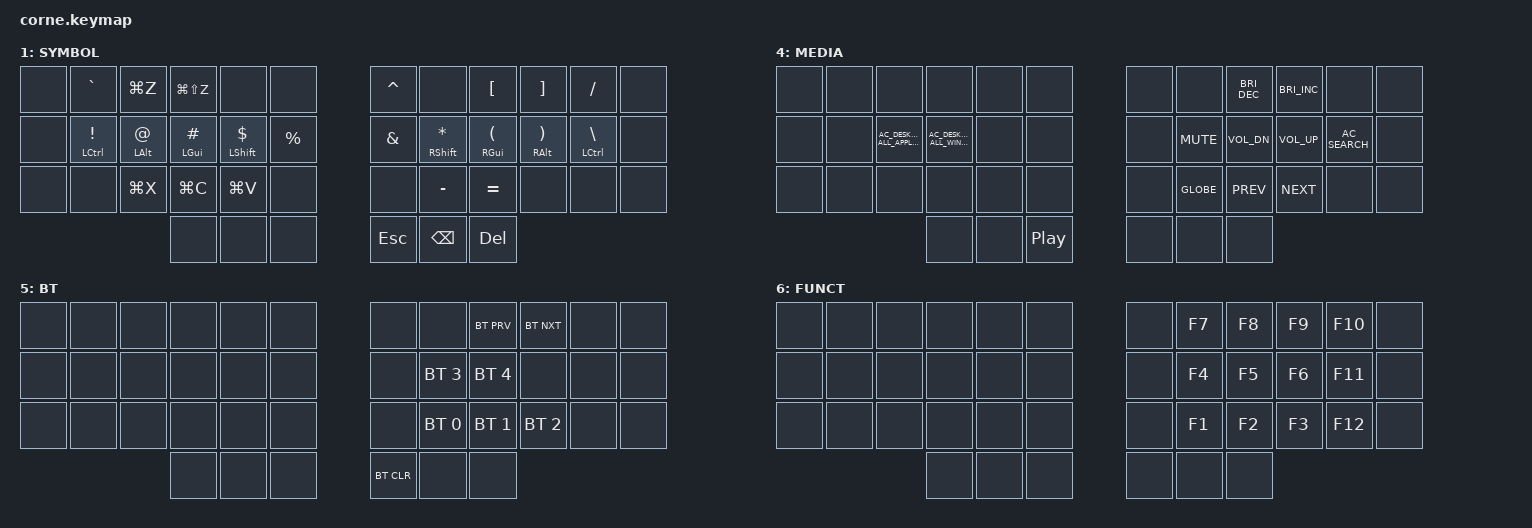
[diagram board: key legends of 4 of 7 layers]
/*
 * Copyright (c) 2020 The ZMK Contributors
 *
 * SPDX-License-Identifier: MIT
 */

#include <behaviors.dtsi>
#include <dt-bindings/zmk/keys.h>
#include <dt-bindings/zmk/bt.h>
#include "./keypos42.h"
#include "./helpers.h"

// Define my layers
#define DEFAULT 0
#define SYM 1
#define NUM 2
#define NAV 3
#define MEDIA 4
#define BT 5
#define FUN 6


// Define custom keys shortform
#define XX &none
#define MEH LG(LA(LCTRL))
#define HYP LS(LG(LA(LCTRL)))
#define REM LA(BSPC)
#define KCUT &kp LG(X)
#define KCOPY &kp LG(C)
#define KPASTE &kp LG(V)
#define KUNDO &kp LG(Z)
#define KREDO &kp LG(LS(Z))
#define MUL &kp KP_MULTIPLY
#define SUB &kp KP_SUBTRACT
#define ADD &kp KP_PLUS
#define DIV &kp KP_DIVIDE
#define KEQ &kp KP_EQUAL
#define KP0 &kp KP_N0
#define K1 &kp KP_N1
#define K2 &kp KP_N2
#define K3 &kp KP_N3
#define K4 &kp KP_N4
#define K5 &kp KP_N5
#define K6 &kp KP_N6
#define C6 KP_N6
#define K7 &kp KP_N7
#define C7 KP_N7
#define K8 &kp KP_N8
#define C8 KP_N8
#define K9 &kp KP_N9
#define VOL_UP &kp C_VOL_UP
#define VOL_DOWN &kp C_VOL_DN
#define BR_UP &kp C_BRIGHTNESS_INC
#define BR_DOWN &kp C_BRIGHTNESS_DEC
#define MUTE &kp K_MUTE
#define PLAY &kp C_PLAY
#define PAUSE &kp C_PAUSE
#define PREV &kp C_PREV
#define NEXT &kp C_NEXT
#define STOP &kp C_STOP
#define SLEEP &kp C_SLEEP
#define POWER &kp C_POWER
#define CALC &kp C_CALCULATOR
#define PP &kp C_PLAY_PAUSE
#define SEARCH &kp C_AC_SEARCH
#define EXPOSE &kp C_AC_DESKTOP_SHOW_ALL_WINDOWS
#define APPS &kp C_AC_DESKTOP_SHOW_ALL_APPLICATIONS
#define PERC &kp PRCNT
#define AMPER &kp AMPS

/* Homerow mods */

#define KEYS_L LT0 LT1 LT2 LT3 LT4 LM0 LM1 LM2 LM3 LM4 LB0 LB1 LB2 LB3 LB4  // left hand
#define KEYS_R RT0 RT1 RT2 RT3 RT4 RM0 RM1 RM2 RM3 RM4 RB0 RB1 RB2 RB3 RB4  // right hand
#define THUMBS LH2 LH1 LH0 RH0 RH1 RH2                                      // thumbs

&lt {
        tapping-term-ms = <200>;
};

&sk {
        release-after-ms = <2000>;
        quick-release;
};

/ {
        combos {
                compatible = "zmk,combos";
                combo_capslock {
                        timeout-ms = <40>;
                        key-positions = <LH1 RH1>;
                        bindings = <&kp CAPS>;
                };
        };
        behaviors {
                hml: left_hand_positional_hold_tap {
                        compatible = "zmk,behavior-hold-tap";
                        label = "LEFT_POSITIONAL_HOLD_TAP";
                        #binding-cells = <2>;
                        flavor = "balanced";
                        tapping-term-ms = <280>;                        // <---[[produces tap if held longer than tapping-term-ms]]
                        require-prior-idle-ms = <180>;
                        quick-tap-ms = <175>;
                        bindings = <&kp>, <&kp>;
                        hold-trigger-key-positions = <KEYS_R THUMBS>;    // <---[[right-hand keys]]
                        hold-trigger-on-release;
                };
                hmr: right_hand_positional_hold_tap {
                        compatible = "zmk,behavior-hold-tap";
                        label = "RIGHT_POSITIONAL_HOLD_TAP";
                        #binding-cells = <2>;
                        flavor = "balanced";
                        tapping-term-ms = <280>;                        // <---[[produces tap if held longer than tapping-term-ms]]
                        require-prior-idle-ms = <180>;
                        quick-tap-ms = <175>;
                        bindings = <&kp>, <&kp>;
                        hold-trigger-key-positions = <KEYS_L THUMBS>;    // <---[[left-hand keys]]
                        hold-trigger-on-release;
                };
        };
        keymap {
                compatible = "zmk,keymap";
                default_layer {
                        label = "BASE";
                        bindings = <
//╭─────────────┬─────────────┬─────────────┬─────────────┬─────────────╮╭─────────────┬─────────────┬─────────────┬─────────────┬─────────────╮
XX  &kp SQT       &kp COMMA     &kp DOT       &kp P           &kp Y         &kp F        &kp G         &kp C         &kp R         &kp L       XX
//├─────────────┼─────────────┼─────────────┼─────────────┼─────────────┤├─────────────┼─────────────┼─────────────┼─────────────┼─────────────┤
XX &hml LCTRL A  &hml LALT O   &hml LGUI E   &hml LSHFT U     &kp I         &kp D       &hmr RSHFT H  &hmr RGUI T   &hmr RALT N   &hmr LCTRL S XX
//├─────────────┼─────────────┼─────────────┼─────────────┼─────────────┤├─────────────┼─────────────┼─────────────┼─────────────┼─────────────┤
XX  &lt FUN SEMI  &kp Q         &kp J         &kp K           &kp X         &kp B        &kp M         &kp W         &kp V         &kp Z       XX
//╰─────────────┴─────────────┼─────────────┼─────────────┼─────────────┤├─────────────┼─────────────┼─────────────┼─────-───────┴─────────────╯
                                &lt BT XX     &lt NUM TAB  &lt SYM REM   &lt NAV SPACE  &sk LSHIFT   &lt MEDIA RET
//                            ╰─────────────┴─────────────┴─────────────╯╰─────────────┴─────────────┴─────────────╯
                        >;
                };
                symbol_layer {
                        label = "SYMBOL";
                        bindings = <
//╭─────────────┬─────────────┬─────────────┬─────────────┬─────────────╮╭─────────────┬─────────────┬─────────────┬─────────────┬─────────────╮
XX  &kp GRAVE       KUNDO          KREDO         XX             XX         &kp CARET         XX        &kp LBKT       &kp RBKT    &kp FSLH     XX
//├─────────────┼─────────────┼─────────────┼─────────────┼─────────────┤├─────────────┼─────────────┼─────────────┼─────────────┼─────────────┤
XX &hml LCTRL EXCL &hml LALT AT &hml LGUI HASH &hml LSHFT DLLR  PERC       AMPER &hmr RSHFT STAR &hmr RGUI LPAR &hmr RALT RPAR &hmr LCTRL BSLH XX
//├─────────────┼─────────────┼─────────────┼─────────────┼─────────────┤├─────────────┼─────────────┼─────────────┼─────────────┼─────────────┤
XX      XX            KCUT         KCOPY          KPASTE         XX          XX            &kp MINUS    &kp EQUAL        XX           XX       XX
//╰─────────────┴─────────────┼─────────────┼─────────────┼─────────────┤├─────────────┼─────────────┼─────────────┼─────-───────┴─────────────╯
                                    XX            XX            XX          &kp ESC        &kp BSPC     &kp DEL     
//                            ╰─────────────┴─────────────┴─────────────╯╰─────────────┴─────────────┴─────────────╯
                        >;
                };
                number_layer {
                        label = "NUMBER";
                        bindings = <
//╭─────────────┬─────────────┬─────────────┬─────────────┬─────────────╮╭─────────────┬─────────────┬─────────────┬─────────────┬─────────────╮
XX  &kp SQT       &kp LBKT       &kp RBKT        XX             XX            KEQ         &kp N7        &kp N8        &kp N9       &kp MINUS   XX
//├─────────────┼─────────────┼─────────────┼─────────────┼─────────────┤├─────────────┼─────────────┼─────────────┼─────────────┼─────────────┤
XX &hml LCTRL XX &hml LALT LPAR &hml LGUI RPAR &hml LSHFT SPACE XX            MUL      &hmr RSHFT N4 &hmr RGUI N5 &hmr RALT N6 &hmr LCTRL PLUS XX
//├─────────────┼─────────────┼─────────────┼─────────────┼─────────────┤├─────────────┼─────────────┼─────────────┼─────────────┼─────────────┤
XX  &kp SEMI      &kp BSPC       &kp REM         XX             XX            DIV         &kp N1        &kp N2        &kp N3        &kp RET    XX
//╰─────────────┴─────────────┼─────────────┼─────────────┼─────────────┤├─────────────┼─────────────┼─────────────┼─────-───────┴─────────────╯
                                    XX           XX             XX         &kp KP_N0      &kp DOT      &kp COMMA
//                            ╰─────────────┴─────────────┴─────────────╯╰─────────────┴─────────────┴─────────────╯
                        >;
                };
                navigation_layer {
                        label = "NAV";
                        bindings = <
//╭─────────────┬─────────────┬─────────────┬─────────────┬─────────────╮╭─────────────┬─────────────┬─────────────┬─────────────┬─────────────╮
XX      XX            XX            XX            XX            XX             XX           KCUT         KCOPY          KPASTE        XX       XX
//├─────────────┼─────────────┼─────────────┼─────────────┼─────────────┤├─────────────┼─────────────┼─────────────┼─────────────┼─────────────┤
XX  &hml LCTRL XX  &hml LALT XX &hml LGUI XX  &hml LSHFT XX     XX            XX          &kp HOME     &kp UP       &kp END       &kp PG_UP    XX
//├─────────────┼─────────────┼─────────────┼─────────────┼─────────────┤├─────────────┼─────────────┼─────────────┼─────────────┼─────────────┤
XX      XX            XX            XX            XX            XX              XX         &kp LEFT     &kp DOWN     &kp RIGHT    &kp PG_DN    XX
//╰─────────────┴─────────────┼─────────────┼─────────────┼─────────────┤├─────────────┼─────────────┼─────────────┼─────────────┴─────────────╯
                                    XX            XX            XX            XX            XX            XX      
//                            ╰─────────────┴─────────────┴─────────────╯╰─────────────┴─────────────┴─────────────╯
                        >;
                };
                media_layer {
                        label = "MEDIA";
                        bindings = <
//╭─────────────┬─────────────┬─────────────┬─────────────┬─────────────╮╭─────────────┬─────────────┬─────────────┬─────────────┬─────────────╮
XX      XX            XX            XX            XX            XX             XX            XX          BR_DOWN         BR_UP          XX     XX
//├─────────────┼─────────────┼─────────────┼─────────────┼─────────────┤├─────────────┼─────────────┼─────────────┼─────────────┼─────────────┤
XX      XX            APPS          EXPOSE        XX            XX              XX            MUTE       VOL_DOWN      VOL_UP        SEARCH    XX
//├─────────────┼─────────────┼─────────────┼─────────────┼─────────────┤├─────────────┼─────────────┼─────────────┼─────────────┼─────────────┤
XX      XX            XX            XX            XX            XX              XX       &kp GLOBE        PREV          NEXT          XX       XX
//╰─────────────┴─────────────┼─────────────┼─────────────┼─────────────┤├─────────────┼─────────────┼─────────────┼─────-───────┴─────────────╯
                                    XX            XX            PP            XX            XX            XX      
//                            ╰─────────────┴─────────────┴─────────────╯╰─────────────┴─────────────┴─────────────╯
                        >;
                };
                bluetooth_layer {
                        label = "BT";
                        bindings = <
//╭─────────────┬─────────────┬─────────────┬─────────────┬─────────────╮╭─────────────┬─────────────┬─────────────┬─────────────┬─────────────╮
XX       XX            XX            XX            XX            XX              XX            XX      &bt BT_PRV     &bt BT_NXT       XX      XX   
//├─────────────┼─────────────┼─────────────┼─────────────┼─────────────┤├─────────────┼─────────────┼─────────────┼─────────────┼─────────────┤
XX      XX            XX            XX            XX            XX              XX       &bt BT_SEL 3 &bt BT_SEL 4       XX            XX      XX
//├─────────────┼─────────────┼─────────────┼─────────────┼─────────────┤├─────────────┼─────────────┼─────────────┼─────────────┼─────────────┤
XX      XX            XX            XX            XX            XX              XX       &bt BT_SEL 0 &bt BT_SEL 1  &bt BT_SEL 2          XX   XX
//╰─────────────┴─────────────┼─────────────┼─────────────┼─────────────┤├─────────────┼─────────────┼─────────────┼─────-───────┴─────────────╯
                                     XX            XX            XX        &bt BT_CLR            XX            XX      
//                            ╰─────────────┴─────────────┴─────────────╯╰─────────────┴─────────────┴─────────────╯
                        >;
                };
                function_layer {
                        label = "FUNCT";
                        bindings = <
//╭─────────────┬─────────────┬─────────────┬─────────────┬─────────────╮╭─────────────┬─────────────┬─────────────┬─────────────┬─────────────╮
XX      XX            XX            XX            XX            XX             XX           &kp F7       &kp F8        &kp F9       &kp F10    XX
//├─────────────┼─────────────┼─────────────┼─────────────┼─────────────┤├─────────────┼─────────────┼─────────────┼─────────────┼─────────────┤
XX      XX            XX            XX            XX            XX             XX           &kp F4       &kp F5        &kp F6       &kp F11    XX
//├─────────────┼─────────────┼─────────────┼─────────────┼─────────────┤├─────────────┼─────────────┼─────────────┼─────────────┼─────────────┤
XX      XX            XX            XX            XX            XX             XX           &kp F1       &kp F2        &kp F3       &kp F12    XX
//╰─────────────┴─────────────┼─────────────┼─────────────┼─────────────┤├─────────────┼─────────────┼─────────────┼─────-───────┴─────────────╯
                                    XX           XX          XX                XX            XX          XX         
//                            ╰─────────────┴─────────────┴─────────────╯╰─────────────┴─────────────┴─────────────╯
                        >;
                };
        };
};
